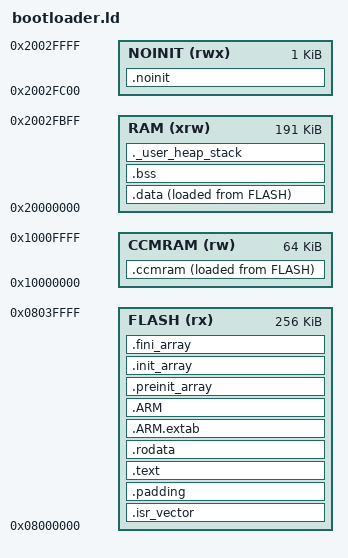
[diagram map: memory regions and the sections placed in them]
/* Custom bootloader linker script, edited from ST's STM32F429IITx_FLASH.ld. */
/* Modifications are:
/* - NOINIT memory area to hold data that survives reset. */
/* - .user_flash sector. Trying to get it placed at 0x08004000 by declaring */
/* - .padding section between .isr_vector and .user_flash. */

/* Entry Point */
ENTRY(Reset_Handler)

/* Highest address of the user mode stack */
_estack = 0x20030000;    /* end of RAM */
/* Generate a link error if heap and stack don't fit into RAM */
_Min_Heap_Size = 0x200;      /* required amount of heap  */
_Min_Stack_Size = 0x400; /* required amount of stack */

/* Specify the memory areas */
MEMORY
{
    FLASH (rx)      : ORIGIN = 0x08000000, LENGTH = 256K /* max. bootloader binary size */
    CCMRAM (rw)     : ORIGIN = 0x10000000, LENGTH = 64K
    RAM (xrw)       : ORIGIN = 0x20000000, LENGTH = 191K /* deduct 1K for NOINIT data */
    NOINIT (rwx)    : ORIGIN = 0x2002FC00, LENGTH = 1K /* NOINIT data will survive reset */
}

/* Define output sections */
SECTIONS
{
    /* The startup code goes first into FLASH */
    .isr_vector :
    {
    . = ALIGN(4);
    KEEP(*(.isr_vector)) /* Vector table */
    . = ALIGN(4);
    } >FLASH

    /* padding to align .user_flash to 0x4000 */
    .padding :
    {
        . = ALIGN(4);
        KEEP(*(.padding))
        . = ALIGN(4);
    } >FLASH

    /* Then comes user flash sector, make sure to get one of the first 4 that are 16K in size
    .user_flash :
    {
      . = 0x08004000
      KEEP(*(.user_flash))
    } >FLASH

  /* The program code and other data goes into FLASH */
  .text :
  {
    . = ALIGN(4);
    *(.text)           /* .text sections (code) */
    *(.text*)          /* .text* sections (code) */
    *(.glue_7)         /* glue arm to thumb code */
    *(.glue_7t)        /* glue thumb to arm code */
    *(.eh_frame)

    KEEP (*(.init))
    KEEP (*(.fini))

    . = ALIGN(4);
    _etext = .;        /* define a global symbols at end of code */
  } >FLASH

  /* Constant data goes into FLASH */
  .rodata :
  {
    . = ALIGN(4);
    *(.rodata)         /* .rodata sections (constants, strings, etc.) */
    *(.rodata*)        /* .rodata* sections (constants, strings, etc.) */
    . = ALIGN(4);
  } >FLASH

  .ARM.extab   : { *(.ARM.extab* .gnu.linkonce.armextab.*) } >FLASH
  .ARM : {
    __exidx_start = .;
    *(.ARM.exidx*)
    __exidx_end = .;
  } >FLASH

  .preinit_array     :
  {
    PROVIDE_HIDDEN (__preinit_array_start = .);
    KEEP (*(.preinit_array*))
    PROVIDE_HIDDEN (__preinit_array_end = .);
  } >FLASH
  .init_array :
  {
    PROVIDE_HIDDEN (__init_array_start = .);
    KEEP (*(SORT(.init_array.*)))
    KEEP (*(.init_array*))
    PROVIDE_HIDDEN (__init_array_end = .);
  } >FLASH
  .fini_array :
  {
    PROVIDE_HIDDEN (__fini_array_start = .);
    KEEP (*(SORT(.fini_array.*)))
    KEEP (*(.fini_array*))
    PROVIDE_HIDDEN (__fini_array_end = .);
  } >FLASH

  .noinit(NOLOAD):
  {
      PROVIDE(__start_noinit_data = .);
      KEEP(*(.noinit))
      PROVIDE(__stop_noinit_data = .);
  } >NOINIT

  /* used by the startup to initialize data */
  _sidata = LOADADDR(.data);

  /* Initialized data sections goes into RAM, load LMA copy after code */
  .data : 
  {
    . = ALIGN(4);
    _sdata = .;        /* create a global symbol at data start */
    *(.data)           /* .data sections */
    *(.data*)          /* .data* sections */

    . = ALIGN(4);
    _edata = .;        /* define a global symbol at data end */
  } >RAM AT> FLASH

  _siccmram = LOADADDR(.ccmram);

  /* CCM-RAM section 
  * 
  * IMPORTANT NOTE! 
  * If initialized variables will be placed in this section,
  * the startup code needs to be modified to copy the init-values.  
  */
  .ccmram :
  {
    . = ALIGN(4);
    _sccmram = .;       /* create a global symbol at ccmram start */
    *(.ccmram)
    *(.ccmram*)
    
    . = ALIGN(4);
    _eccmram = .;       /* create a global symbol at ccmram end */
  } >CCMRAM AT> FLASH

  
  /* Uninitialized data section */
  . = ALIGN(4);
  .bss :
  {
    /* This is used by the startup in order to initialize the .bss secion */
    _sbss = .;         /* define a global symbol at bss start */
    __bss_start__ = _sbss;
    *(.bss)
    *(.bss*)
    *(COMMON)

    . = ALIGN(4);
    _ebss = .;         /* define a global symbol at bss end */
    __bss_end__ = _ebss;
  } >RAM

  /* User_heap_stack section, used to check that there is enough RAM left */
  ._user_heap_stack :
  {
    . = ALIGN(8);
    PROVIDE ( end = . );
    PROVIDE ( _end = . );
    . = . + _Min_Heap_Size;
    . = . + _Min_Stack_Size;
    . = ALIGN(8);
  } >RAM

  

  /* Remove information from the standard libraries */
  /DISCARD/ :
  {
    libc.a ( * )
    libm.a ( * )
    libgcc.a ( * )
  }

  .ARM.attributes 0 : { *(.ARM.attributes) }
}


